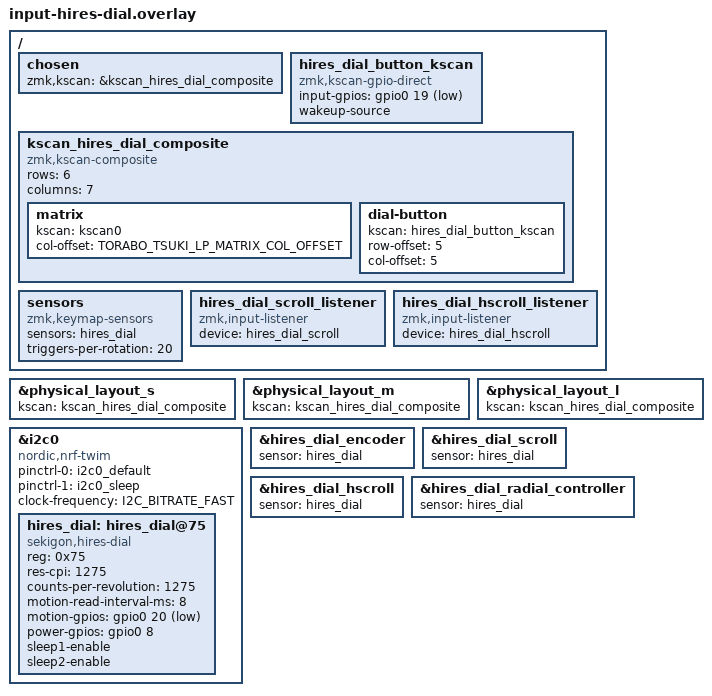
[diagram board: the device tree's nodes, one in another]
#include <zephyr/dt-bindings/gpio/gpio.h>
#include <zephyr/dt-bindings/i2c/i2c.h>
#include <zephyr/dt-bindings/input/input-event-codes.h>
#include <zephyr/dt-bindings/gpio/nordic-nrf-gpio.h>

/ {
    chosen {
        zmk,kscan = &kscan_hires_dial_composite;
    };

    hires_dial_button_kscan: hires_dial_button_kscan {
        compatible = "zmk,kscan-gpio-direct";
        input-gpios = <&gpio0 19 (GPIO_ACTIVE_LOW | GPIO_PULL_UP)>;
        wakeup-source;
    };

    kscan_hires_dial_composite: kscan_hires_dial_composite {
        compatible = "zmk,kscan-composite";
        rows = <6>;
        columns = <7>;

        matrix {
            kscan = <&kscan0>;
            col-offset = <TORABO_TSUKI_LP_MATRIX_COL_OFFSET>;
        };

        dial-button {
            kscan = <&hires_dial_button_kscan>;
            row-offset = <5>;
            col-offset = <5>;
        };
    };

    sensors {
        compatible = "zmk,keymap-sensors";
        sensors = <&hires_dial>;
        triggers-per-rotation = <20>;
    };

    hires_dial_scroll_listener {
        compatible = "zmk,input-listener";
        device = <&hires_dial_scroll>;
    };

    hires_dial_hscroll_listener {
        compatible = "zmk,input-listener";
        device = <&hires_dial_hscroll>;
    };
};

&physical_layout_s {
    kscan = <&kscan_hires_dial_composite>;
};

&physical_layout_m {
    kscan = <&kscan_hires_dial_composite>;
};

&physical_layout_l {
    kscan = <&kscan_hires_dial_composite>;
};

&i2c0 {
    status = "okay";
    compatible = "nordic,nrf-twim";
    pinctrl-0 = <&i2c0_default>;
    pinctrl-1 = <&i2c0_sleep>;
    pinctrl-names = "default", "sleep";
    clock-frequency = <I2C_BITRATE_FAST>;

    hires_dial: hires_dial@75 {
        status = "okay";
        compatible = "sekigon,hires-dial";
        reg = <0x75>;
        res-cpi = <1275>;
        counts-per-revolution = <1275>;
        motion-read-interval-ms = <8>;
        motion-gpios = <&gpio0 20 (GPIO_ACTIVE_LOW | GPIO_PULL_UP)>;
        power-gpios = <&gpio0 8 (GPIO_ACTIVE_HIGH | NRF_GPIO_DRIVE_H0H1)>;
        sleep1-enable;
        sleep2-enable;
    };
};

&hires_dial_encoder {
    sensor = <&hires_dial>;
};

&hires_dial_scroll {
    sensor = <&hires_dial>;
};

&hires_dial_hscroll {
    sensor = <&hires_dial>;
};

&hires_dial_radial_controller {
    sensor = <&hires_dial>;
};
